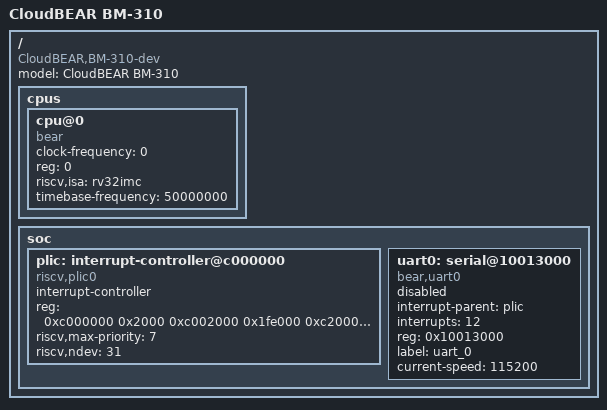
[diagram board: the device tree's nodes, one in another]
/*
 * Copyright (c) 2018 CloudBEAR
 *
 * SPDX-License-Identifier: Apache-2.0
 */

/ {
	#address-cells = <1>;
	#size-cells = <1>;
	compatible = "CloudBEAR,BM-310-dev";
	model = "CloudBEAR BM-310";
	cpus {
		#address-cells = <1>;
		#size-cells = <0>;
		cpu@0 {
			clock-frequency = <0>;
			compatible = "bear", "riscv";
			device_type = "cpu";
			reg = <0>;
			riscv,isa = "rv32imc";
			status = "okay";
			timebase-frequency = <50000000>;
		};
	};
	soc {
		#address-cells = <1>;
		#size-cells = <1>;
		ranges;
		plic: interrupt-controller@c000000 {
			#interrupt-cells = <1>;
			compatible = "riscv,plic0";
			interrupt-controller;
			reg = <0xc000000 0x2000
			       0xc002000 0x1fe000
			       0xc200000 0x2000000>;
			reg-names = "prio", "irq_en", "reg";
			riscv,max-priority = <7>;
			riscv,ndev = <31>;
		};
		uart0: serial@10013000 {
			compatible = "bear,uart0";
			interrupt-parent = <&plic>;
			interrupts = <12>;
			reg = <0x10013000>;
			reg-names = "control";
			label = "uart_0";
			status = "enabled";
			current-speed = <115200>;
		};
	};
};
